# PIC32CM5112SG00064 device description
Architecture: CORTEX-M23; Family: PIC32CM; Series: PIC32CMSG00
Registers are 32-bit, read-write, reset 0x0 unless marked. A register's access mark holds for its fields unless they carry their own. Offsets are from the block's base; [hi:lo] are bit positions; {n}, {i} and the like mark numbered series; 'fields as' and 'values as' point back to an identical list; <NAME> marks a mode.

## FUSES_BOOTCFG1 — Defines FUSES module data
Instances: FUSES_BOOTCFG1 0x0A002000, FUSES_BOOTCFG1A 0x0A000000
0x00 DATA1 reset not defined
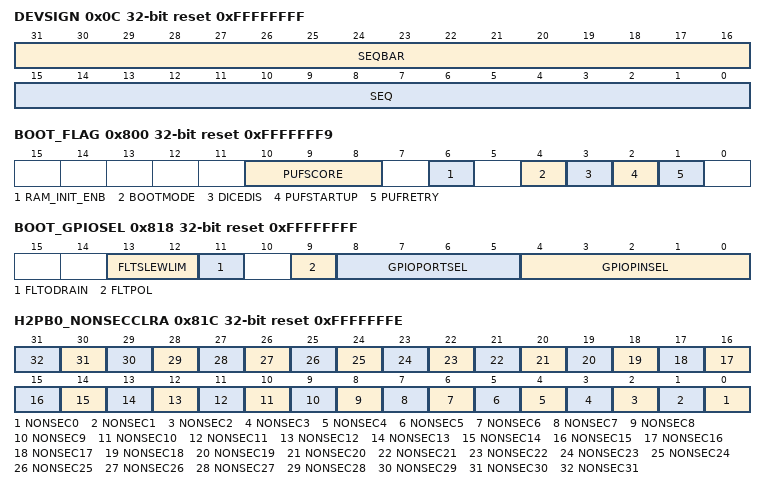
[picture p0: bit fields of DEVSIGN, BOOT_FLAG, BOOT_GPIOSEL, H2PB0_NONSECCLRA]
0x0C DEVSIGN reset 0xFFFFFFFF
  [31:16] SEQBAR — Sequence number BAR
  [15:0] SEQ — Sequence number
0x800 BOOT_FLAG reset 0xFFFFFFF9 — BOOT CODE FLAGS REGISTER
  [10:8] PUFSCORE — PUF Score Value
  [6] RAM_INIT_ENB — RAM ECC Enable
  [4] BOOTMODE
  [3] DICEDIS — Device Identifier Composition Engine Disable
  [2] PUFSTARTUP — PUF Start Up Mode
  [1] PUFRETRY
0x810 DICE_CDI_INDEX reset 0xFFFFFFFF — Mapped Fuse Register
  [6:0] DICE_CDI_INDEX
0x814 DICE_FW_HASH_INDEX reset 0xFFFFFFFF — Mapped Fuse Register
  [6:0] DICE_FW_HASH_INDEX
0x818 BOOT_GPIOSEL reset 0xFFFFFFFF — BOOT EXTERNAL NOTIFICATION IO PIN REGISTER
  [13:12] FLTSLEWLIM — Selects Driver Slew Rate Selection for Boot External Notification Signal
  [11] FLTODRAIN — Open Drain Control for Boot External Notification Signal
  [9] FLTPOL — Selects IO Port for Boot External Notification Signal
  [8:5] GPIOPORTSEL — Selects IO Port for Boot External Notification Signal
  [4:0] GPIOPINSEL — Selects IO Port Pin for Boot External Notification Signal
0x81C H2PB0_NONSECCLRA reset 0xFFFFFFFE — Non-Security Clear Register A
  [n] NONSEC{n} (n=0..31) — non-security bit for APB Slave k, k=0..31
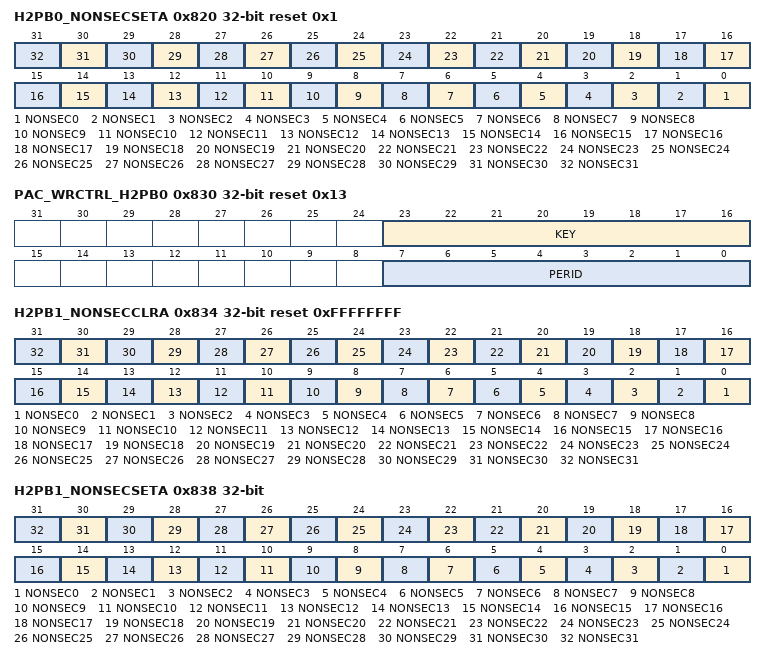
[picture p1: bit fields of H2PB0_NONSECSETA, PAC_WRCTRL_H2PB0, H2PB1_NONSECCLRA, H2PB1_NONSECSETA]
0x820 H2PB0_NONSECSETA reset 0x1 — Non-Security SET Register A
  [n] NONSEC{n} (n=0..31) — non-security bit for APB Slave k, k=0..31
0x830 PAC_WRCTRL_H2PB0 reset 0x13 — Write Control Register
  [23:16] KEY — Peripheral Access Control Key
    0=OFF (OFF - No Action); 1=CLEAR (CLEAR - Clear the peripheral write protection); 2=SET (SET - Set the peripheral write protection); 3=LOCK (LOCK - Set and Lock the write protection state of the peripheral until the next reset)
  [7:0] PERID — Peripheral Identifier
0x834 H2PB1_NONSECCLRA reset 0xFFFFFFFF — Non-Security Clear Register A
  [n] NONSEC{n} (n=0..31) — non-security bit for APB Slave k, k=0..31
0x838 H2PB1_NONSECSETA — Non-Security SET Register A
  [n] NONSEC{n} (n=0..31) — non-security bit for APB Slave k, k=0..31
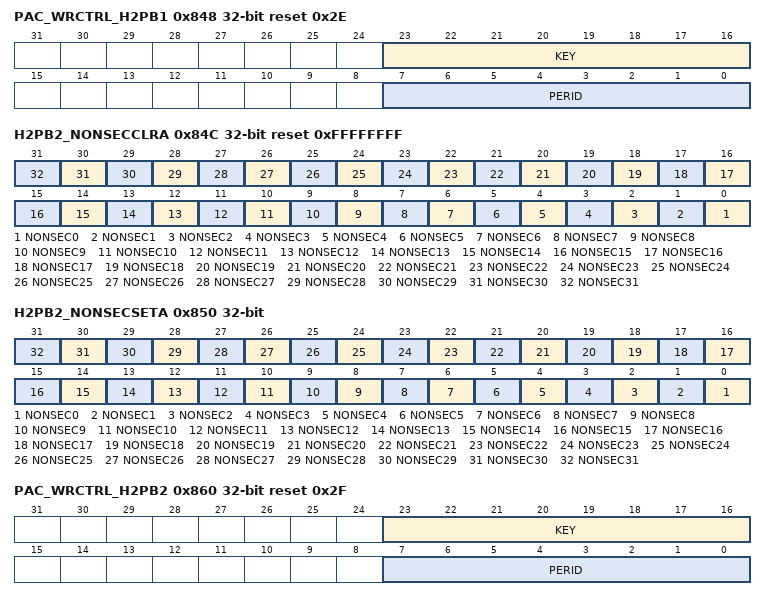
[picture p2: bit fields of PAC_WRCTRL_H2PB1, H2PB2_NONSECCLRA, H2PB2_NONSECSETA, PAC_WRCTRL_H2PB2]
0x848 PAC_WRCTRL_H2PB1 reset 0x2E — Write Control Register
  fields as PAC_WRCTRL_H2PB0
0x84C H2PB2_NONSECCLRA reset 0xFFFFFFFF — Non-Security Clear Register A
  [n] NONSEC{n} (n=0..31) — non-security bit for APB Slave k, k=0..31
0x850 H2PB2_NONSECSETA — Non-Security SET Register A
  [n] NONSEC{n} (n=0..31) — non-security bit for APB Slave k, k=0..31
0x860 PAC_WRCTRL_H2PB2 reset 0x2F — Write Control Register
  fields as PAC_WRCTRL_H2PB0
0x864 IDAU_RCTRL_BFM reset 0x5C000000 — Region Control
  [31:24] CMD <BLOCK> — IDAU Region Control BFM Command
    90=CLRNONSEC (Clear IDAU region x Non-Secure State of block ARG (RSTATUSB[x].NONSEC[ARG]=0)); 91=SETNONSEC (Set IDAU region x Non-Secure State of block ARG (RSTATUSB[x].NONSEC[ARG]=1))
  [4:0] ARG <BLOCK> — IDAU Region Control BFM Command Argument (Block ID)
  [31:24] CMD <WATERMARK> — IDAU Region Control BFM Command
    92=WRSZ (Write IDAU region x Size (RSTATUSB[x].SIZE=ARG))
  [23:0] ARG <WATERMARK> — IDAU Region Control BFM Command Argument (Watermark)
0x868 IDAU_RCTRL_PFMANS reset 0x5C000000 — Region Control
  [31:24] CMD <BLOCK> — IDAU Region Control PFMAN Command
    values as IDAU_RCTRL_BFM.CMD<BLOCK>
  [4:0] ARG <BLOCK> — IDAU Region Control PFMANS Command Argument (Block ID)
  [31:24] CMD <WATERMARK> — IDAU Region Control PFMAN Command
    92=WRSZ (Write IDAU region x Size (RSTATUSB[x].SIZE=ARG))
  [23:0] ARG <WATERMARK> — IDAU Region Control PFMAN Command Argument (Watermark)
0x86C IDAU_RCTRL_PFMANSC reset 0x5C000000 — Region Control
  [31:24] CMD <BLOCK> — IDAU Region Control PFMANSC Command
    values as IDAU_RCTRL_BFM.CMD<BLOCK>
  [4:0] ARG <BLOCK> — IDAU Region Control PFMANSC Command Argument (Block ID)
  [31:24] CMD <WATERMARK> — IDAU Region Control PFMANSC Command
    92=WRSZ (Write IDAU region x Size (RSTATUSB[x].SIZE=ARG))
  [23:0] ARG <WATERMARK> — IDAU Region Control PFMANSC Command Argument (Watermark)
0x870 IDAU_RCTRL_DRM reset 0x5C000000 — Region Control
  [31:24] CMD <BLOCK> — IDAU Region Control DRM Command
    values as IDAU_RCTRL_BFM.CMD<BLOCK>
  [4:0] ARG <BLOCK> — IDAU Region Control DRM Command Argument (Block ID)
  [31:24] CMD <WATERMARK> — IDAU Region Control DRM Command
    92=WRSZ (Write IDAU region x Size (RSTATUSB[x].SIZE=ARG))
  [23:0] ARG <WATERMARK> — IDAU Region Control DRM Command Argument (Watermark)
0x874 IDAU_CTRL_EN reset 0xA5010000 — Control
  [31:16] CMD — IDAU Enable Command Register
    0xA501=ENABLE (Module Enable); 0xA502=DISABLE (Module Disable)
0x878 IDAU_CTRL_WLCK reset 0xFFFFFFFF — Control
  [31:16] CMD — IDAU Write Lock Command Register
    0xA503=WLCK (Write Lock)
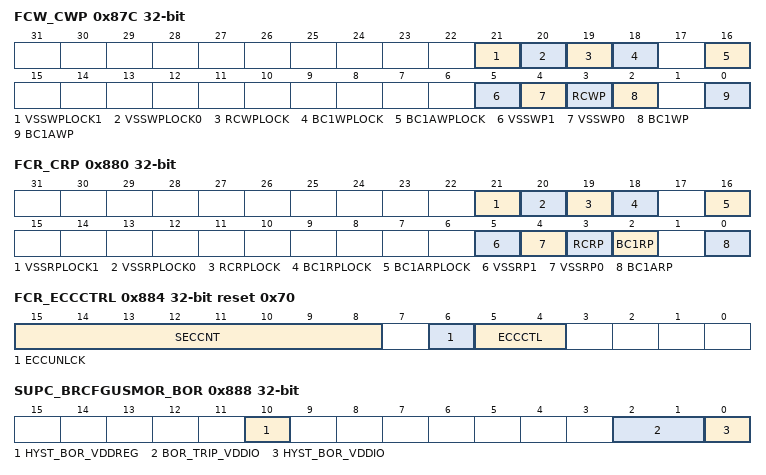
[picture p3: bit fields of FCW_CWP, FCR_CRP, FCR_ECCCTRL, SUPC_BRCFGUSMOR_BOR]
0x87C FCW_CWP — CFM Page Write Protect REGISTER
  [21] VSSWPLOCK1 — Panel 1 Lock Write Protection VSSn
    0=UNLOCKED (The Lock &amp; Write Protect bits for this Page are NOT Locked and can be modified); 1=LOCKED (The Lock &amp; Write Protect bits for this Page are Locked and cannot be modified)
  [20] VSSWPLOCK0 — Panel 1 Lock Write Protection VSSn
    values as VSSWPLOCK1
  [19] RCWPLOCK — Panel 1 Lock Write Protection ROMCfg
    values as VSSWPLOCK1
  [18] BC1WPLOCK — Panel 1 Lock Write Protection BootCfg1
    values as VSSWPLOCK1
  [16] BC1AWPLOCK — Panel 1 Lock Write Protection BootCfg1A
    values as VSSWPLOCK1
  [5] VSSWP1 — Panel 1 Write Protect VSSn
    0=DISABLE (Erase and Write Protection for this Page is Disabled); 1=ENABLE (Erase and Write Protection for this Page is Enabled)
  [4] VSSWP0 — Panel 1 Write Protect VSSn
    values as VSSWP1
  [3] RCWP — Panel 1 Write Protect ROMCfg
    values as VSSWP1
  [2] BC1WP — Panel 1 Write Protect BootCfg1
    values as VSSWP1
  [0] BC1AWP — Panel 1 Write Protect BootCfg1A
    values as VSSWP1
0x880 FCR_CRP — CFM Page Read Protection Register
  [21] VSSRPLOCK1 — Panel 1 Lock Read Protection VSSn
    0=UNLOCKED (The Lock &amp; Read Protect bits for this Page are NOT Locked and can be modified); 1=LOCKED (The Lock &amp; Read Protect bits for this Page are Locked and cannot be modified)
  [20] VSSRPLOCK0 — Panel 1 Lock Read Protection VSSn
    values as VSSRPLOCK1
  [19] RCRPLOCK — Panel 1 Lock Read Protection ROMCfg
    values as VSSRPLOCK1
  [18] BC1RPLOCK — Panel 1 Lock Read Protection BootCfg1
    values as VSSRPLOCK1
  [16] BC1ARPLOCK — Panel 1 Lock Read Protection BootCfg1A
    values as VSSRPLOCK1
  [5] VSSRP1 — Panel 1 Read Protect VSSn
    0=DISABLE (Read Protection for this Page is Disabled); 1=ENABLE (Read Protection for this Page is Enabled)
  [4] VSSRP0 — Panel 1 Read Protect VSSn
    values as VSSRP1
  [3] RCRP — Panel 1 Read Protect ROMCfg
    values as VSSRP1
  [2] BC1RP — Panel 1 Read Protect BootCfg1
    values as VSSRP1
  [0] BC1ARP — Panel 1 Read Protect BootCfg1A
    values as VSSRP1
0x884 FCR_ECCCTRL reset 0x70 — ECC Control REGISTER
  [15:8] SECCNT — Flash SEC Count
  [6] ECCUNLCK — NVM ECC Mode Control Unlock
    0=LOCKED (ECCUNLCK and ECCCTL[1:0] cannot be written); 1=UNLOCKED (ECCUNLCK and ECCCTL[1:0] can be written)
  [5:4] ECCCTL — NVM ECC Mode Control - restricts one or more NVMOPs
    0=STRICT (ECC Writes with ECC Reads (NVMOP = Single Program Operation disabled)); 1=DYNAMIC (Dynamic Writes with Dynamic Reads); 2=ECC (ECC Writes with Dynamic Reads (NVMOP = Single Program Operation disabled)); 3=DISABLE (Dynamic Writes with No Error Check Reads)
0x888 SUPC_BRCFGUSMOR_BOR — Boot Rom Configurable SMOR User CFG BOR register
  [10] HYST_BOR_VDDREG — Refer to pwr_smor_[nn]_v2 DOS document for details.
    0=LOW (Low Hysteresis (default)); 1=HIGH (High Hysteresis)
  [2:1] BOR_TRIP_VDDIO — Nominal BOR Trip, Refer to pwr_smor_[nn]_v2 DOS document for details.
    0=1.68V (default); 1=2.2V; 2=2.64V; 3=2.93V
  [0] HYST_BOR_VDDIO — Refer to pwr_smor_[nn]_v2 DOS document for details.
    0=LOW (Low Hysteresis (default)); 1=HIGH (High Hysteresis)
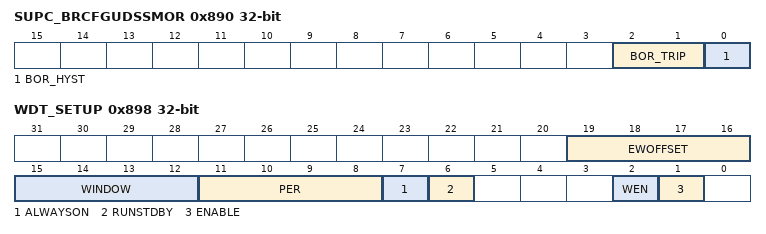
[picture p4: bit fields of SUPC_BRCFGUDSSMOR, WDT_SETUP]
0x890 SUPC_BRCFGUDSSMOR — Boot Rom Configurable DSSMOR User CFG register
  [2:1] BOR_TRIP — Nominal BOR Trip, Refer to pwr_smor_ds_[nn]_v2 DOS document for details.
    0=1.61V (default); 1=2.12V; 2=2.55V; 3=2.8V
  [0] BOR_HYST — Refer to pwr_smor_ds_[nn]_v2 DOS document for details.
    0=LOW (Low Hysteresis (default)); 1=HIGH (High Hysteresis)
0x894 SUPC_BRCFGUCP0 reset 0x1 — Boot Rom Configurable CHARGE PUMP User CFG register
  [3:0] CP — Refer to vreg_chrg_pump_v4 DOS document for details.
    0=Clock gating trip optimized for low output threshold voltage (3.01V); 1=Clock gating trip optimized for high output threshold voltage (3.2V) (default)
0x898 WDT_SETUP
  [19:16] EWOFFSET — Early Warning Interrupt Time Offset
    0=CYC8 (8 clock cycles); 1=CYC16 (16 clock cycles); 2=CYC32 (32 clock cycles); 3=CYC64 (64 clock cycles); 4=CYC128 (128 clock cycles); 5=CYC256 (256 clock cycles); 6=CYC512 (512 clock cycles); 7=CYC1024 (1024 clock cycles); 8=CYC2048 (2048 clock cycles); 9=CYC4096 (4096 clock cycles); 10=CYC8192 (8192 clock cycles); 11=CYC16384 (16384 clock cycles)
  [15:12] WINDOW — Window Mode Time-Out Period
    values as EWOFFSET
  [11:8] PER — Time-Out Period
    values as EWOFFSET
  [7] ALWAYSON
  [6] RUNSTDBY — Run During Standby
  [2] WEN — Watchdog Timer Window Mode Enable
  [1] ENABLE
